# CH32V00Xxx register map
Vendor: WCH Ltd.; File version: 1.0
Registers are 32-bit, read-write, reset 0x0 unless marked. A register's access mark holds for its fields unless they carry their own. Offsets are from the block's base; [hi:lo] are bit positions; lines under a group give offsets from that group; {n}, {i} and the like mark numbered series.

## ADC_TKEY — Analog to digital converter
Base 0x40012400
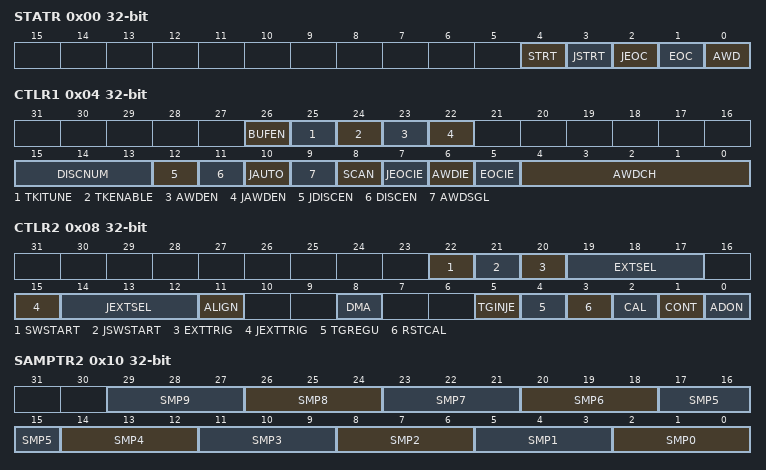
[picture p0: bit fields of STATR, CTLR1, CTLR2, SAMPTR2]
0x00 STATR — status register
  [4] STRT — Regular channel start flag
  [3] JSTRT — Injected channel start flag
  [2] JEOC — Injected channel end of conversion
  [1] EOC — Regular channel end of conversion
  [0] AWD — Analog watchdog flag
0x04 CTLR1 — control register 1/TKEY_V_CTLR
  [26] BUFEN — ADC buffer enable
  [25] TKITUNE — Touchkey current regulation
  [24] TKENABLE — Touchkey module enable control
  [23] AWDEN — Analog watchdog enable on regular channels
  [22] JAWDEN — Analog watchdog enable on injected channels
  [15:13] DISCNUM — Discontinuous mode channel count
  [12] JDISCEN — Discontinuous mode on injected channels
  [11] DISCEN — Discontinuous mode on regular channels
  [10] JAUTO — Automatic injected group conversion
  [9] AWDSGL — Enable the watchdog on a single channel in scan mode
  [8] SCAN — Scan mode enable
  [7] JEOCIE — Interrupt enable for injected channels
  [6] AWDIE — Analog watchdog interrupt enable
  [5] EOCIE — Interrupt enable for EOC
  [4:0] AWDCH — Analog watchdog channel select bits
0x08 CTLR2 — control register 2
  [22] SWSTART — Start conversion of regular channels
  [21] JSWSTART — Start conversion of injected channels
  [20] EXTTRIG — External trigger conversion mode for regular channels
  [19:17] EXTSEL — External event select for regular group
  [15] JEXTTRIG — External trigger conversion mode for injected channels
  [14:12] JEXTSEL — External event select for injected group
  [11] ALIGN — Data alignment
  [8] DMA — Direct memory access mode
  [5] TGINJE — External trigger events that inject transitions
  [4] TGREGU — External firing events for regular channel transitions
  [3] RSTCAL — Reset calibration
  [2] CAL — A/D calibration
  [1] CONT — Continuous conversion
  [0] ADON — A/D converter ON / OFF
0x0C SAMPTR1 — sample time register 1
  [2:0] SMP10 — Channel 10 sample time selection
0x10 SAMPTR2 — sample time register 2
  [3n+2:3n] SMP{n} (n=0..9) — Channel {n} sample time selection
{0x10+4i} IOFR{i} (i=1..4) — injected channel data offset register {i}
  [11:0] JOFFSET{i} — Data offset for injected channel {i}
0x24 WDHTR — watchdog higher threshold register
  [11:0] HT — Analog watchdog higher threshold
0x28 WDLTR — watchdog lower threshold register
  [11:0] LT — Analog watchdog lower threshold
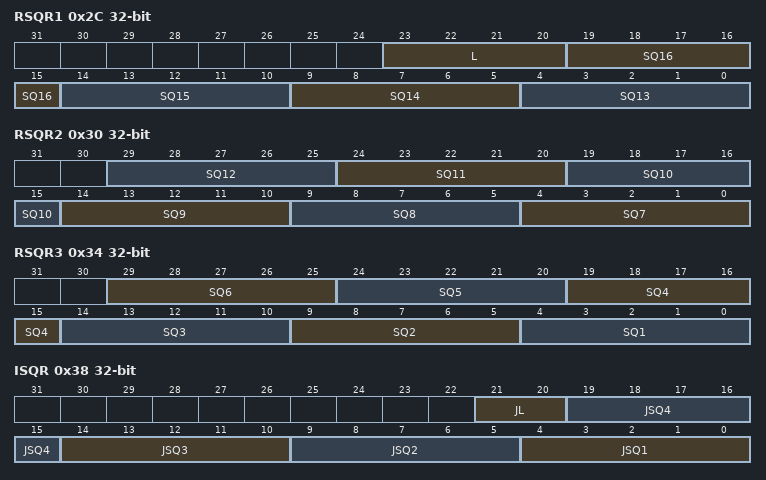
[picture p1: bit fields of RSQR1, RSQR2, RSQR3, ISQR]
0x2C RSQR1 — regular sequence register 1
  [23:20] L — Regular channel sequence length
  [5n-61:5n-65] SQ{n} (n=13..16) — {n}th conversion in regular sequence
0x30 RSQR2 — regular sequence register 2
  [5n-31:5n-35] SQ{n} (n=7..12) — {n}th conversion in regular sequence
0x34 RSQR3 — regular sequence register 3
  [29:25] SQ6 — 6th conversion in regular sequence
  [24:20] SQ5 — 5th conversion in regular sequence
  [19:15] SQ4 — 4th conversion in regular sequence
  [14:10] SQ3 — 3rd conversion in regular sequence
  [9:5] SQ2 — 2nd conversion in regular sequence
  [4:0] SQ1 — 1st conversion in regular sequence
0x38 ISQR — injected sequence register
  [21:20] JL — Injected sequence length
  [19:15] JSQ4 — 4th conversion in injected sequence
  [14:10] JSQ3 — 3rd conversion in injected sequence
  [9:5] JSQ2 — 2nd conversion in injected sequence
  [4:0] JSQ1 — 1st conversion in injected sequence
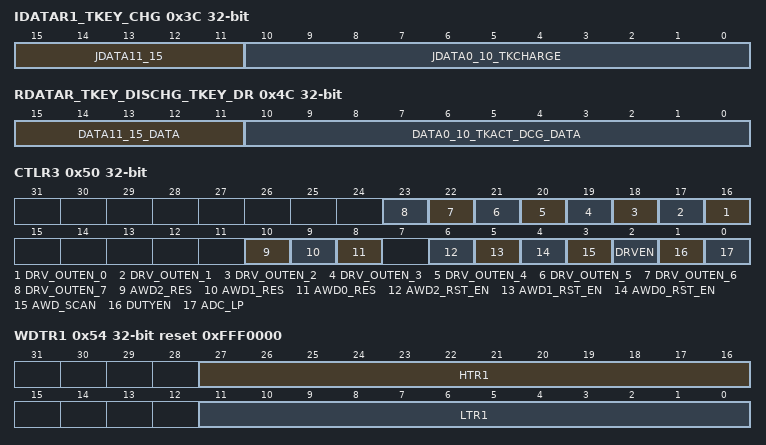
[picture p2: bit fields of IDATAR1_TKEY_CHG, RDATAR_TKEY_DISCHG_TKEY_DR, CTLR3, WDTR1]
0x3C IDATAR1_TKEY_CHG access per field — injected data register 1_Charge time configuration register
  [15:11] JDATA11_15 ro — Injected data
  [10:0] JDATA0_10_TKCHARGE read-only_write-only — Injected data_Touch key charge data offset for injected channel x
{0x38+4i} IDATAR{i} ro (i=2..4) — injected data register {i}
  [15:0] IDATA — Injected data
0x4C RDATAR_TKEY_DISCHG_TKEY_DR read-only_write-only — regular data register_start and discharge time register_tkey data register
  [15:11] DATA11_15_DATA — Regular data_converted data
  [10:0] DATA0_10_TKACT_DCG_DATA — Regular data_converted data
0x50 CTLR3 — Control register 3
  [n+16] DRV_OUTEN_{n} (n=0..7) — Touchkey channel {n} masking enable
  [10] AWD2_RES — Analog Watchdog 2 compares the results
  [9] AWD1_RES — Analog Watchdog 1 compares the results
  [8] AWD0_RES — Analog Watchdog 0 compares the results
  [6] AWD2_RST_EN — Analog Watchdog 2 output reset enable bit
  [5] AWD1_RST_EN — Analog Watchdog 1 output reset enable bit
  [4] AWD0_RST_EN — Analog Watchdog 0 output reset enable bit
  [3] AWD_SCAN — Analog Watchdog sans the enable
  [2] DRVEN — Touchkey multiple masking enable bit
  [1] DUTYEN — ADC clock duty control bit
  [0] ADC_LP — ADC low-power mode control bit
0x54 WDTR1 reset 0xFFF0000 — ADC watchdog 1 threshold register
  [27:16] HTR1 — Analog watchdog higher threshold setting value
  [11:0] LTR1 — Analog watchdog lower threshold setting value
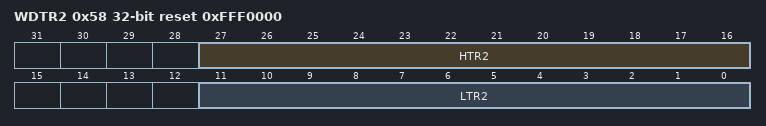
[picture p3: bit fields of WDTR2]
0x58 WDTR2 reset 0xFFF0000 — ADC watchdog 2 threshold register
  [27:16] HTR2 — Analog watchdog higher threshold setting value
  [11:0] LTR2 — Analog watchdog lower threshold setting value
